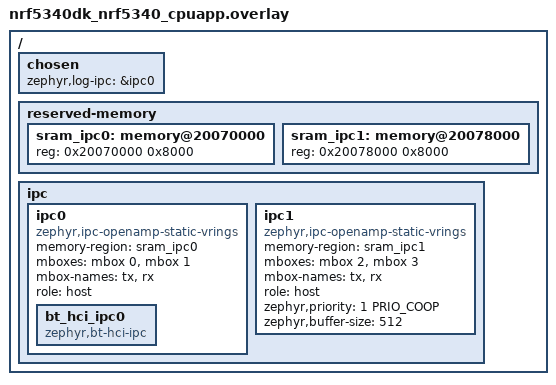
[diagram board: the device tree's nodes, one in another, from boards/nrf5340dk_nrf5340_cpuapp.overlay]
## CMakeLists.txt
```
#
# Copyright (c) 2022 Nordic Semiconductor ASA
#
# SPDX-License-Identifier: Apache-2.0
#

cmake_minimum_required(VERSION 3.20.0)

find_package(Zephyr REQUIRED HINTS $ENV{ZEPHYR_BASE})

if(NOT (CONFIG_BOARD_NRF5340DK_NRF5340_CPUAPP OR
   CONFIG_BOARD_NRF5340BSIM_NRF5340_CPUAPP))
  message(FATAL_ERROR "${BOARD}${BOARD_QUALIFIERS} is not supported for this sample")
endif()

project(log_multidomain)

target_sources(app PRIVATE src/main.c)

if(CONFIG_IPC_SERVICE)
  target_sources(app PRIVATE src/ipc_service.c)
endif()
```

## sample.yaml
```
sample:
  name: Logging in multi-domain environment
common:
  sysbuild: true
  tags: ipc
tests:
  sample.logging.multidomain.ipc_static_vrings:
    platform_allow:
      - nrf5340dk/nrf5340/cpuapp
      - nrf5340bsim/nrf5340/cpuapp
    integration_platforms:
      - nrf5340dk/nrf5340/cpuapp
      - nrf5340bsim/nrf5340/cpuapp
    harness: console
    harness_config:
      type: multi_line
      ordered: false
      regex:
        - "Hello World!"
        - "app: IPC-service HOST \\[INST 1\\] demo started"
        - "app: loop: 0"
        - "app: ipc open"
        - "app: wait for bound"
        - "app: bounded"
        - "app: REMOTE \\[1\\]: 0"
        - "app: HOST \\[1\\]: 1"
        - "app: IPC-service HOST \\[INST 1\\] demo ended."
```

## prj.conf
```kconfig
CONFIG_PRINTK=y
CONFIG_HEAP_MEM_POOL_SIZE=4096

CONFIG_IPC_SERVICE=y
CONFIG_IPC_SERVICE_BACKEND_RPMSG=y
CONFIG_MBOX=y

CONFIG_OPENAMP=y
CONFIG_OPENAMP_SLAVE=n

CONFIG_LOG=y
CONFIG_LOG_BUFFER_SIZE=8192
CONFIG_IPC_SERVICE_LOG_LEVEL_INF=y
CONFIG_LOG_MULTIDOMAIN=y
CONFIG_LOG_LINK_IPC_SERVICE=y

CONFIG_ASSERT=y
#CONFIG_LOG_PRINTK=y
CONFIG_LOG_PROCESSING_LATENCY_US=300000
```

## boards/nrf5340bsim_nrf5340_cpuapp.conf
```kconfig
CONFIG_MBOX_NRFX_IPC=y
# For the mailbox to be initialized logger initialization is delayed like in real HW
CONFIG_LOG_PROCESS_THREAD=y
CONFIG_LOG_MODE_DEFERRED=y
```

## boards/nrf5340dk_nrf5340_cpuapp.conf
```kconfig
CONFIG_BOARD_ENABLE_CPUNET=y
CONFIG_MBOX_NRFX_IPC=y
CONFIG_LOG_BACKEND_UART_ASYNC=y
CONFIG_UART_ASYNC_API=y
CONFIG_UART_0_ASYNC=y
```

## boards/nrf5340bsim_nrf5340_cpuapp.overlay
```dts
/*
 * Copyright (c) 2023 Nordic Semiconductor ASA
 *
 * SPDX-License-Identifier: Apache-2.0
 */

#include "nrf5340dk_nrf5340_cpuapp.overlay"
```

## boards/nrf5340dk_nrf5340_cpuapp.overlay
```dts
/*
 * Copyright (c) 2022 Nordic Semiconductor ASA
 *
 * SPDX-License-Identifier: Apache-2.0
 */

#include <zephyr/dt-bindings/ipc_service/static_vrings.h>

/ {
	chosen {
		/delete-property/ zephyr,ipc_shm;
		zephyr,log-ipc = &ipc0;
	};

	reserved-memory {
		/delete-node/ memory@20070000;

		sram_ipc0: memory@20070000 {
			reg = <0x20070000 0x8000>;
		};

		sram_ipc1: memory@20078000 {
			reg = <0x20078000 0x8000>;
		};
	};

	ipc {
		/delete-node/ ipc0;

		ipc0: ipc0 {
			compatible = "zephyr,ipc-openamp-static-vrings";
			memory-region = <&sram_ipc0>;
			mboxes = <&mbox 0>, <&mbox 1>;
			mbox-names = "tx", "rx";
			role = "host";
			status = "okay";

			bt_hci_ipc0: bt_hci_ipc0 {
			     status = "okay";
			     compatible = "zephyr,bt-hci-ipc";
			};
		};

		ipc1: ipc1 {
			compatible = "zephyr,ipc-openamp-static-vrings";
			memory-region = <&sram_ipc1>;
			mboxes = <&mbox 2>, <&mbox 3>;
			mbox-names = "tx", "rx";
			role = "host";
			zephyr,priority = <1 PRIO_COOP>;
			zephyr,buffer-size = <512>;
			status = "okay";
		};
	};
};
```

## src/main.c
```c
/*
 * Copyright (c) 2022 Nordic Semiconductor ASA
 *
 * SPDX-License-Identifier: Apache-2.0
 */

#include <zephyr/kernel.h>
#include <zephyr/sys/printk.h>
#include <zephyr/logging/log.h>
LOG_MODULE_REGISTER(app);

int main(void)
{
	printk("Hello World! %s\n", CONFIG_BOARD);
	return 0;
}
```

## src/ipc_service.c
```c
/*
 * Copyright (c) 2022 Nordic Semiconductor ASA
 *
 * SPDX-License-Identifier: Apache-2.0
 */

#include <zephyr/kernel.h>
#include <zephyr/device.h>
#include <zephyr/ipc/ipc_service.h>
#include <zephyr/logging/log.h>
LOG_MODULE_DECLARE(app);

#define STACKSIZE	4096
#define PRIORITY	K_PRIO_PREEMPT(2)

K_THREAD_STACK_DEFINE(ipc1_stack, STACKSIZE);
static volatile uint8_t ipc1_received_data;
static K_SEM_DEFINE(ipc1_bound_sem, 0, 1);
static K_SEM_DEFINE(ipc1_data_sem, 0, 1);

/*
 * ==> THREAD 1 (IPC instance 1) <==
 */

static void ipc1_ept_bound(void *priv)
{
	k_sem_give(&ipc1_bound_sem);
}

static void ipc1_ept_recv(const void *data, size_t len, void *priv)
{
	ipc1_received_data = *((uint8_t *) data);

	k_sem_give(&ipc1_data_sem);
}

static struct ipc_ept_cfg ipc1_ept_cfg = {
	.name = "ipc1",
	.cb = {
		.bound    = ipc1_ept_bound,
		.received = ipc1_ept_recv,
	},
};

static void ipc1_entry(void *dummy0, void *dummy1, void *dummy2)
{
	ARG_UNUSED(dummy0);
	ARG_UNUSED(dummy1);
	ARG_UNUSED(dummy2);

	const struct device *ipc1_instance;
	unsigned char message = 0;
	struct ipc_ept ipc1_ept;
	int ret;

	LOG_INF("IPC-service HOST [INST 1] demo started");

	k_sleep(K_MSEC(1000));

	ipc1_instance = DEVICE_DT_GET(DT_NODELABEL(ipc1));

	ret = ipc_service_open_instance(ipc1_instance);
	if (ret < 0 && ret != -EALREADY) {
		LOG_ERR("ipc_service_open_instance() failure");
		return;
	}

	LOG_INF("ipc open %d", ret);
	ret = ipc_service_register_endpoint(ipc1_instance, &ipc1_ept, &ipc1_ept_cfg);
	if (ret < 0) {
		LOG_ERR("ipc_service_register_endpoint() failure");
		return;
	}

	k_sem_take(&ipc1_bound_sem, K_FOREVER);

	while (message < 100) {
		ret = ipc_service_send(&ipc1_ept, &message, sizeof(message));
		if (ret < 0) {
			LOG_ERR("send_message(%d) failed with ret %d", message, ret);
			break;
		}

		k_sem_take(&ipc1_data_sem, K_FOREVER);
		message = ipc1_received_data;

		LOG_INF("HOST [1]: %d", message);
		message++;
	}

	LOG_INF("IPC-service HOST [INST 1] demo ended.");
}

K_THREAD_DEFINE(ipc1_thread_id, STACKSIZE, ipc1_entry, NULL, NULL, NULL, PRIORITY, 0, 0);
```
